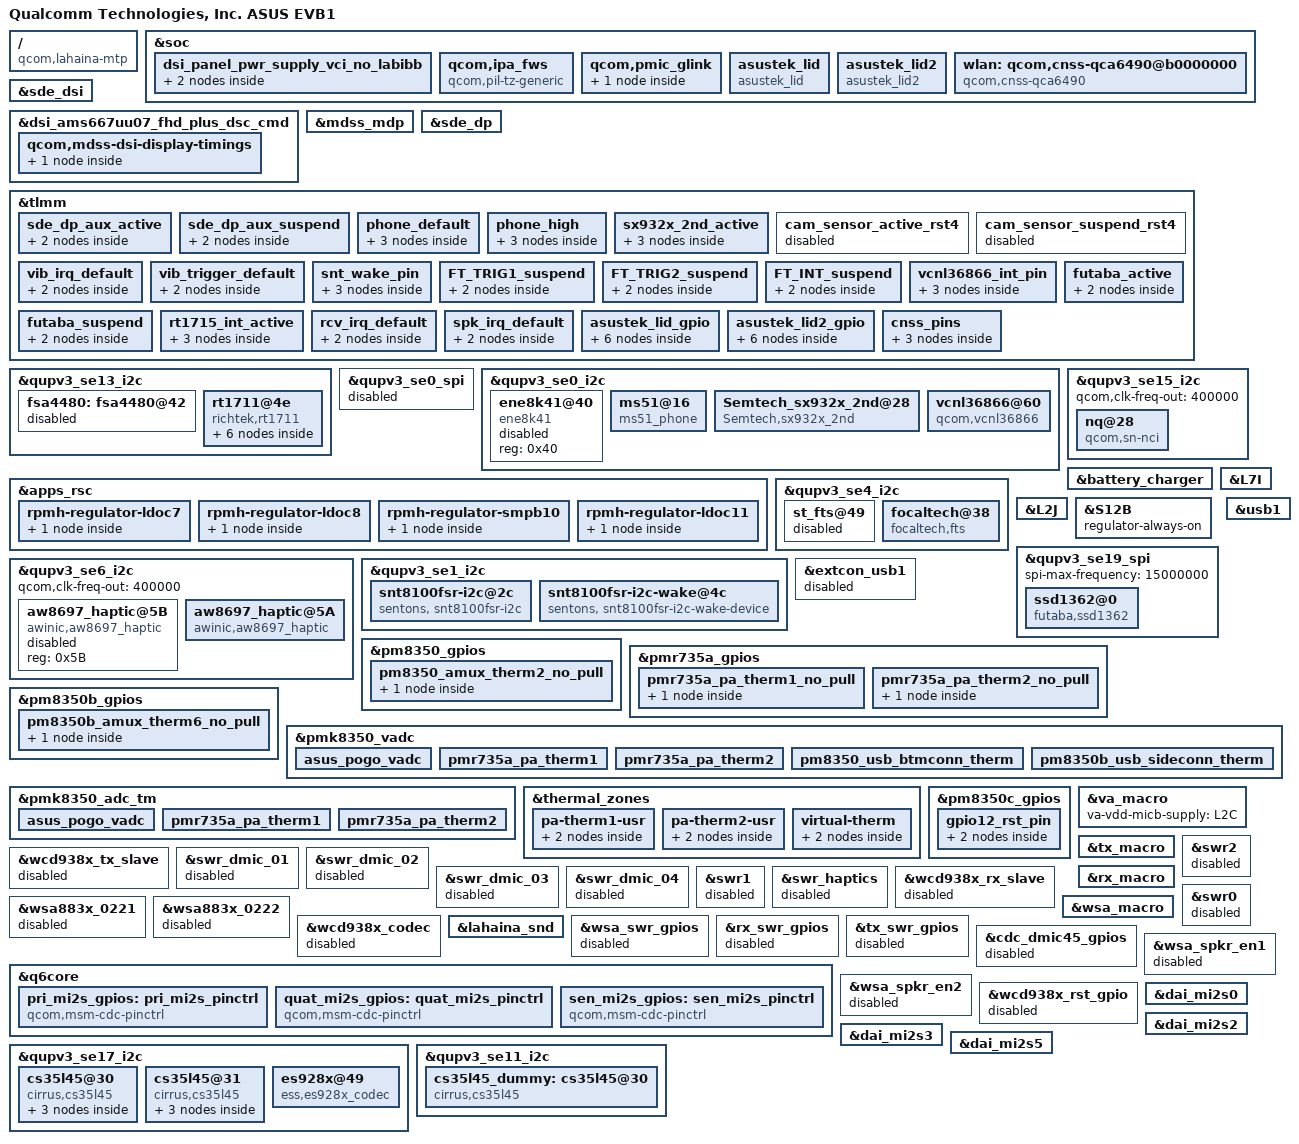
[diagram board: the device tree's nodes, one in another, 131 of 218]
/dts-v1/;
/plugin/;

#include "lahaina-mtp.dtsi"
/* ASUS BSP Display +++ */
#include "dsi-panel-ams667uu07-fhd-plus-dsc-cmd.dtsi"

/* ASUS BSP Camera +++ */
#include "camera/zs673ks-camera-sensor-mtp.dtsi"

/ {
	model = "Qualcomm Technologies, Inc. ASUS EVB1";
	compatible = "qcom,lahaina-mtp", "qcom,lahaina", "qcom,mtp";
	qcom,board-id = <0x10008 0>;
};

/*   ====================================
*    overlay for display - start
*    ====================================
*/
&soc {
	dsi_panel_pwr_supply_vci_no_labibb: dsi_panel_pwr_supply_vci_no_labibb {
		#address-cells = <1>;
		#size-cells = <0>;

		qcom,panel-supply-entry@0 {
			reg = <0>;
			qcom,supply-name = "vddio";
			qcom,supply-min-voltage = <1800000>;
			qcom,supply-max-voltage = <1800000>;
			qcom,supply-enable-load = <60700>;
			qcom,supply-disable-load = <80>;
		};

		qcom,panel-supply-entry@1 {
			reg = <1>;
			qcom,supply-name = "vdd";
			qcom,supply-min-voltage = <3000000>;
			qcom,supply-max-voltage = <3000000>;
			qcom,supply-enable-load = <10000>;
			qcom,supply-disable-load = <0>;
			qcom,supply-post-on-sleep = <0>;
			qcom,supply-pre-off-sleep = <10>;
		};
	};

};

&sde_dsi {
	/delete-property/ avdd-supply;
	qcom,dsi-default-panel = <&dsi_ams667uu07_fhd_plus_dsc_cmd>;

};

&dsi_ams667uu07_fhd_plus_dsc_cmd {
	qcom,panel-supply-entries = <&dsi_panel_pwr_supply_vci_no_labibb>;
	qcom,mdss-dsi-bl-pmic-control-type = "bl_ctrl_dcs";
	qcom,mdss-dsi-bl-min-level = <1>;
	qcom,mdss-dsi-bl-max-level = <4095>;

	qcom,platform-te-gpio = <&tlmm 82 0>; // default is 82
	qcom,platform-reset-gpio = <&tlmm 24 0>;
	qcom,platform-en-gpio = <&tlmm 74 0>;

	qcom,ulps-enabled;
	qcom,dsi-select-clocks = "mux_byte_clk0", "mux_pixel_clk0";
	qcom,mdss-dsi-display-timings {
		timing@0 {
			qcom,mdss-dsi-panel-phy-timings = [00 14 05 05 13 1E 05
				05 06 02 04 00 12 0A];
			qcom,display-topology = <2 2 1>;
			qcom,default-topology-index = <0>;
		};
	};
};

&mdss_mdp {
	qcom,sde-mixer-display-pref = "primary", "none", "none",
				"none", "none", "none";
};

&sde_dp {
	/delete-property/ qcom,dp-aux-switch;
	qcom,dp-gpio-aux-switch;

	qcom,aux-en-gpio = <&tlmm 93 0>;
	qcom,aux-sel-gpio = <&pm8350c_gpios 1 0x0>;


	pinctrl-names = "mdss_dp_active", "mdss_dp_sleep";
	pinctrl-0 = <&sde_dp_aux_active >;
	pinctrl-1 = <&sde_dp_aux_suspend>;
};

&tlmm {
	/delete-property/ display_panel_avdd_default;

	sde_dp_aux_active: sde_dp_aux_active {
		mux {
			pins = "gpio93";
			function = "gpio";
		};

		config {
			pins = "gpio93";
			bias-disable = <0>; /* no pull */
			drive-strength = <8>;
		};
	};

	sde_dp_aux_suspend: sde_dp_aux_suspend {
		mux {
			pins = "gpio93";
			function = "gpio";
		};

		config {
			pins = "gpio93";
			bias-disable = <0>; /* no pull */
			drive-strength = <2>;
		};
	};
	//ASUS_BSP+++ "AntennaSwap"
	phone_default {
	    phone_default_1: phone_default_1{
		    mux {
			    pins = "gpio83";
			    function = "gpio";
		    };
		    config {
			    pins = "gpio83";
			    bias-pull-up;
			    output-low;
		    };
	    };
	};

	phone_high {
	    phone_high_1: phone_high_1{
		    mux {
			    pins = "gpio83";
			    function = "gpio";
		    };
		    config {
			    pins = "gpio83";
			    bias-pull-up;
			    output-high;
		    };
	    };
	};
	//ASUS_BSP--- "AntennaSwap"
};

&qupv3_se13_i2c {
	fsa4480: fsa4480@42 {
		status = "disable";
	};
};
/*   ====================================
*    overlay for display - end
*    ====================================
*/

/*    ====================================
 *    overlay for lahainap-v2.dtsi - start
 *    ====================================
 */

/*    ====================================
 *    overlay for lahainap-v2.dtsi - end
 *    ====================================
 */



/*    ====================================
 *    overlay for lahainap.dtsi - start
 *    ====================================
 */

/*    ====================================
 *    overlay for lahainap.dtsi - end
 *    ====================================
*/



/*    ====================================
 *    overlay for lahaina-mtp.dtsi - start
 *    ====================================
 */

&qupv3_se0_spi {
	status = "disable";
};

&qupv3_se0_i2c {
	status = "ok";

	ene8k41@40 {
		compatible = "ene8k41";
		reg = <0x40>;
		//ene,aura_3p3_en = <&tlmm 108 0x0>;
		//pinctrl-names = "active";
		//pinctrl-0 = <&aura_3p3_en>;
		status = "disabled";
	};

	ms51@16 {
		compatible = "ms51_phone";
		reg = <0x16>;

		//panel = <&dsi_r66451_fhd_video &dsi_r66451_fhd_dsc_cmd_dim>;
		nuvoton,aura_3p3_en = <0 0 0>;
		nuvoton,front_led_en = <&pm8350c_gpios 2 0x0>;
		nuvoton,logo_5p0_en = <&pm8350c_gpios 3 0x0>;
		nuvoton,hw_stage = <0>;

		vdd-supply = <&pm8350c_l7>;
		nuvoton,vdd-voltage = <3300000 3300000>;
		nuvoton,vdd-current = <140000>;
	};
};

&apps_rsc {
	rpmh-regulator-ldoc7 {
		L7C: pm8350c_l7: regulator-pm8350c-l7 {
			regulator-min-microvolt = <3300000>;
			regulator-max-microvolt = <3300000>;
			qcom,init-voltage = <3300000>;
		};
	};
};

//ASUS_BSP BerylHou +++ 
//"touch FT3518U" +++
 &qupv3_se4_i2c {
  	status = "ok";

  	st_fts@49 {
		status = "disable";
	};
  	
	focaltech@38 {
		compatible = "focaltech,fts";
		reg = <0x38>;
		interrupt-parent = <&tlmm>;
		interrupts = <23 0x2008>;
		focaltech,reset-gpio = <&tlmm 22 0x00>;
		focaltech,irq-gpio = <&tlmm 23 0x2008>;
		focaltech,vddio = <&tlmm 131 0x00>;
		focaltech,max-touch-number = <10>;
		focaltech,display-coords = <0 0 1080 2400>;

		vdd-supply = <&L3C>;
		vcc_i2c-supply = <&L8C>;

		pinctrl-names = "pmx_ts_active", "pmx_ts_suspend","pmx_ts_release";
		pinctrl-0 = <&ts_active>;
		pinctrl-1 = <&ts_int_suspend &ts_reset_suspend>;
		pinctrl-2 = <&ts_release>;

//		panel = <&dsi_ams667uu07_fhd_plus_dsc_cmd>;
//			 &dsi_r66451_amoled_video>;
	};
};

&qupv3_se15_i2c{
	status = "ok";
	qcom,clk-freq-out = <400000>;

	nq@28 {
		compatible = "qcom,sn-nci";
		reg = <0x29>;
		qcom,sn-irq = <&tlmm 87 0x00>;
		qcom,sn-ven = <&tlmm 62 0x00>;
		qcom,sn-firm = <&tlmm 86 0x00>;
		qcom,sn-clkreq = <&tlmm 63 0x00>;
		interrupt-parent = <&tlmm>;
		interrupts = <87 0>;
		interrupt-names = "nfc_irq";
		pinctrl-names = "nfc_active", "nfc_suspend";
		pinctrl-0 = <&nfc_int_active &nfc_enable_active
				&nfc_clk_req_active &nfc_fwdl_active>;
		pinctrl-1 = <&nfc_int_suspend &nfc_enable_suspend
				&nfc_clk_req_suspend &nfc_fwdl_suspend>;
	};
};

//"touch FT3518U" ---
//cap sensor 1  SX9325" +++
/* &qupv3_se15_i2c{
	status = "ok";
	Semtech_sx932x@28 {
	compatible = "Semtech,sx932x";
	reg = <0x28>;
	//interrupt-parent = <&tlmm>;
	//interrupts = <99 0>;
	pinctrl-names = "sx932x_1st_active";
	pinctrl-0 = <&sx932x_1st_active>;
		
	Semtech,nirq-gpio = <&tlmm 99 0x00>;
	status = "ok";
	Semtech,reg-num = <45>; // total registers number to initialize
	Semtech,reg-init  = /bits/ 8 < 0x10 0x1C
                                0x11 0x21
                                0x14 0x00
                                0x15 0x00
                                0x20 0x20
                                0x23 0x00
                                0x24 0x47
                                0x26 0x00
                                0x27 0x47
                                0x28 0x39
                                0x29 0x2D
                                0x2A 0x36
                                0x2B 0x07
                                0x2C 0x12
                                0x2D 0x08
                                0x30 0x21
                                0x31 0x0B
                                0x32 0x20
                                0x33 0x20
                                0x34 0x0C
                                0x35 0x00
                                0x36 0x8E
                                0x37 0xB3
                                0x40 0x00
                                0x41 0x00
                                0x42 0x00
                                0x43 0x00
                                0x44 0x00
                                0x45 0x05
                                0x46 0x00
                                0x47 0x00
                                0x48 0x00
                                0x49 0x00
                                0x4A 0x00
                                0x4B 0x00
                                0x4C 0x00
                                0x50 0x14
                                0x51 0x70
                                0x52 0x20
                                0x02 0x00
                                0x05 0x6F
                                0x06 0x00
                                0x07 0x80
                                0x08 0x01
                                0x03 0x0F>;
	};
 };
 
 &tlmm{
	sx932x_active {
		sx932x_1st_active: sx932x_1st_active {
			mux {
				pins = "gpio99";
				function = "gpio";
			};
			config {
				pins = "gpio99";
				bias-pull-up;
				drive-strength = <6>;
			};
		};
	};
  };
*/
//"cap sensor 1  SX9325" ---
//"cap sensor 2  SX9325" +++
 &qupv3_se0_i2c{
	status = "ok";
	Semtech_sx932x_2nd@28 {
	compatible = "Semtech,sx932x_2nd";
	reg = <0x28>;
	pinctrl-names = "sx932x_2nd_active";
	pinctrl-0 = <&sx932x_2nd_active>;
		
	Semtech,nirq-gpio = <&tlmm 91 0x00>;
	status = "ok";	/**/
	Semtech,reg-num = <45>; /* total registers number to initialize*/
	Semtech,reg-init  = /bits/ 8 < 0x10 0x1C
                                0x11 0x21
                                0x14 0x00
                                0x15 0x00
                                0x20 0x20
                                0x23 0x00
                                0x24 0x47
                                0x26 0x00
                                0x27 0x47
                                0x28 0x39
                                0x29 0x2D
                                0x2A 0x36
                                0x2B 0x07
                                0x2C 0x12
                                0x2D 0x08
                                0x30 0x21
                                0x31 0x0B
                                0x32 0x20
                                0x33 0x20
                                0x34 0x0C
                                0x35 0x00
                                0x36 0x8E
                                0x37 0xB3
                                0x40 0x00
                                0x41 0x00
                                0x42 0x00
                                0x43 0x00
                                0x44 0x00
                                0x45 0x05
                                0x46 0x00
                                0x47 0x00
                                0x48 0x00
                                0x49 0x00
                                0x4A 0x00
                                0x4B 0x00
                                0x4C 0x00
                                0x50 0x14
                                0x51 0x70
                                0x52 0x20
                                0x02 0x00
                                0x05 0x6F
                                0x06 0x00
                                0x07 0x80
                                0x08 0x01
                                0x03 0x0F>;
	};
};

&tlmm{
	sx932x_2nd_active {
		sx932x_2nd_active: sx932x_2nd_active {
			mux {
				pins = "gpio91";
				function = "gpio";
			};
			config {
				pins = "gpio91";
				bias-pull-up;
				drive-strength = <6>;
			};
		};
	};
};
//"cap sensor 2  SX9325" ---
//ASUS_BSP BerylHou --- 

//ASUS_BSP: haptic vibrator+++

&tlmm {
		cam_sensor_active_rst4: cam_sensor_active_rst4 {
			status = "disable";
		};
		cam_sensor_suspend_rst4: cam_sensor_suspend_rst4 {
			status = "disable";
		};

		vib_irq_default: vib_irq_default{
			mux {
				pins = "gpio98";
				function = "gpio";
			};

			config {
				pins = "gpio98";
				drive-strength = <2>;
				bias-pull-up;
				input-enable;
				};
		};

		vib_trigger_default: vib_trigger_default{
			mux {
				pins = "gpio97";
				function = "gpio";
			};

			config {
				pins = "gpio97";
				drive-strength = <2>;
				bias-disable;
				output-low;
			};
		};
};

//ASUS_BSP: aw haptic +++
&qupv3_se6_i2c {
	status = "ok";
	#address-cells = <1>;
	#size-cells = <0>;

	//+++for 400kHz i2c clock
	qcom,clk-freq-out = <400000>;
	//---

	aw8697_haptic@5B {
		compatible = "awinic,aw8697_haptic";
		reg = <0x5B>;
		status = "disabled";
	};

	aw8697_haptic@5A {
		compatible = "awinic,aw8697_haptic";
		reg = <0x5A>;
		interrupt-parent = <&tlmm>;
		interrupts = <98 0>; // set type in driver IRQ_TYPE_NONE
		irq-gpio = <&tlmm 98 0>; // set type in driver IRQ_TYPE_NONE
		vib_mode = < 0 >;   /*mode:   RAM mode->0; CONT mode -> 1*/
		vib_f0_pre = < 1500 >; // 150Hz
		vib_f0_cali_percen = < 7 >;
		vib_cont_drv_lev = < 100 >; // 2*1.414*255/6.1
		vib_cont_drv_lvl_ov = < 100 >;
		vib_cont_td = < 0x006c >;
		vib_cont_zc_thr = < 0x0ff1 >;
		vib_cont_num_brk = < 3 >;
		vib_f0_coeff = < 260 >; /*Don't modify it    2.604167*/
		vib_f0_trace_parameter = < 0x05 0x03 0x02 0x0f >;
		vib_bemf_config = < 0x10 0x08 0x03 0xf8 >;
		vib_sw_brake = < 0x2c >;
		vib_tset = < 0x12 >;
		vib_r_spare = < 0x68 >;
		vib_bstdbg = < 0x30 0xeb 0xd4 0 0 0 >;
		pinctrl-names = "default";
		pinctrl-states = "default";
		pinctrl-0 = <&vib_irq_default>;
		status = "okay";
	};
};
//ASUS_BSP: aw haptic ---
//ASUS_BSP: haptic vibrator---

//[+++] ASUS_BSP : Add for battery_charger
&battery_charger {
	PMI_MUX_EN = <&pm8350_gpios 2 0x0>;
	POGO_OTG_EN = <&tlmm 3 0x0>;
};
//[---] ASUS_BSP : Add for battery_charger

// ASUS_BSP +++ ClayWang vcnl36866
&qupv3_se0_i2c {
        status = "ok";
            vcnl36866@60 {
			compatible = "qcom,vcnl36866";
			reg = <0x60>;
			pinctrl-names = "alsps_gpio_no_pull";
			pinctrl-0 = <&vcnl36866_default>;
			qcom,alsps-gpio = <&tlmm 89 0x0>;
			vcc_psensor-supply = <&pm8350c_l7>;
			
		};
};

&apps_rsc {
	// ASUS BSP +++ Clay vcnl36866
	rpmh-regulator-ldoc8 {
		L8C: pm8350c_l8: regulator-pm8350c-l8 {
			regulator-always-on;	/* ASUS BSP Always Enable 1.8V for I2C & Sensors */
		};
	};

	// ASUS BSP --- Clay vcnl36866
	// ASUS BSP +++ Clay Grip
	rpmh-regulator-smpb10 {
		S10B: pm8350_s10: regulator-pm8350-s10 {
			regulator-min-microvolt = <1800000>;
			regulator-max-microvolt = <1800000>;
			qcom,init-voltage = <1800000>;
		};
	};
	// ASUS BSP --- Clay Grip
	
};

//ASUS_BSP RIL+++
&soc {
	qcom,ipa_fws {
		compatible = "qcom,pil-tz-generic";
		vdd-3.0-antenna-supply = <&pm8350c_l11>;
		pinctrl-names = "phone_default", "phone_high";
		pinctrl-0 = <&phone_default_1>;
		pinctrl-1 = <&phone_high_1>;
		phone-asus_ant_83 = <&tlmm 83 0>;
	};
};

&apps_rsc {
	rpmh-regulator-ldoc11 {
		L11C: pm8350c_l11: regulator-pm8350c-l11 {
			regulator-min-microvolt = <2850000>;
			regulator-max-microvolt = <2850000>;
			qcom,init-voltage = <2850000>;
		};
	};
};
//ASUS_BSP RIL---
 
// ASUS_BSP Grip +++
&qupv3_se1_i2c {
	status = "ok";
	snt8100fsr-i2c@2c {
		reg = <0x2c>;
		compatible = "sentons, snt8100fsr-i2c";
		
		qcom,snt-host1-gpio = <&tlmm 165 0x0>;
		qcom,snt-trig0-gpio = <&tlmm 155 0x0>;
		qcom,snt-trig1-gpio = <&tlmm 154 0x0>;
		//qcom,snt-trig2-gpio = <&tlmm 66 0x0>;
		//qcom,snt-trig3-gpio = <&tlmm 167 0x0>;
		snt-id-gpio = <&tlmm 132 GPIO_ACTIVE_HIGH>;
		//snt,gpio_reset = <&tlmm 4 0x0>;
		vcc_grip_2v8-supply = <&pm8008i_l7>;
		vcc_grip_1v2-supply = <&pm8008j_l2>;
		vcc_grip_1v2Base-supply = <&pm8350_s12>;
		vcc_grip_1v8-supply = <&pm8350_s10>;
		
		pinctrl-names = "gpio12_rst_on", "gpio12_rst_off", "snt_wake", "FT_TRIG1_suspend", "FT_TRIG2_suspend", "FT_INT_suspend";
		pinctrl-0 = <&gpio12_rst_pin_default>;
		pinctrl-1 = <&gpio12_rst_off>;
		pinctrl-2 = <&snt_wake>;
		pinctrl-3 = <&FT_TRIG1_suspend>;
		pinctrl-4 = <&FT_TRIG2_suspend>;
		pinctrl-5 = <&FT_INT_suspend>;
		rst_gpios = <&pm8350c_gpios 4 GPIO_ACTIVE_HIGH>;
		//rst_gpios = <&tlmm 167 GPIO_ACTIVE_HIGH>;
	};
	snt8100fsr-i2c-wake@4c {
		reg = <0x4c>;
		wake-device = <1>;
		compatible = "sentons, snt8100fsr-i2c-wake-device";
	};
};

&tlmm {
	snt_wake_pin {
		snt_wake: snt_wake {
			mux {
				pins = "gpio85";
				function = "gpio";
			};
			config {
				pins = "gpio85";
				bias-disable = <0>; /* no pull */
				drive-strength = <2>;
			};
		};
	};
	FT_TRIG1_suspend: FT_TRIG1_suspend {
		mux {
			pins = "gpio155";
			function = "gpio";
		};

		config {
			pins = "gpio155";
			bias-disable = <0>; /* no pull */
			drive-strength = <2>;
		};
	};

	FT_TRIG2_suspend: FT_TRIG2_suspend {
		mux {
			pins = "gpio154";
			function = "gpio";
		};

		config {
			pins = "gpio154";
			bias-disable = <0>; /* no pull */
			drive-strength = <2>;
		};
	};

	FT_INT_suspend: FT_INT_suspend {
		mux {
			pins = "gpio165";
			function = "gpio";
		};

		config {
			pins = "gpio165";
			bias-disable = <0>; /* no pull */
			drive-strength = <2>;
		};
	};
	// ASUS_BSP +++ ClayWang vcnl36866
	vcnl36866_int_pin {
		vcnl36866_default: vcnl36866_default {
			mux {
				pins = "gpio89";
				function = "gpio";
			};
			config {
				pins = "gpio89";
				bias-disable = <0>; /* no pull */
				drive-strength = <2>;
			};
		};
	};
	// ASUS_BSP --- ClayWang vcnl36866
};

&L7I {
	regulator-min-microvolt = <2800000>;
	regulator-max-microvolt = <2800000>;
	qcom,min-dropout-voltage = <300000>;
};
&L2J {
	regulator-max-microvolt = <1256000>;
	qcom,min-dropout-voltage = <0>;
};
&S12B {
	regulator-always-on;
};
// ASUS_BSP Grip ---

//ASUS_BSP PMOLED +++
&qupv3_se19_spi {
	status = "ok";
	spi-max-frequency = <15000000>;

	ssd1362@0 {
		compatible = "futaba,ssd1362";
		reg = <0>;
		spi-max-frequency = <15000000>;
		futaba,id-gpio = <&tlmm 75 0>;
		futaba,reset-gpio = <&tlmm 120 0>;
		futaba,dc-gpio = <&tlmm 121 0>;
		futaba,pwren-gpio = <&tlmm 122 0>;

		pinctrl-names = "futaba_active", "futaba_suspend";
		pinctrl-0 = <&futaba_active>;
		pinctrl-1 = <&futaba_suspend>;
	};
};

&tlmm {
/* futaba pmoled pins */
	futaba_active: futaba_active {
		mux {
			pins = "gpio75", "gpio120", "gpio121", "gpio122";
			function = "gpio";
		};
	config {
		pins = "gpio75", "gpio120", "gpio121", "gpio122";
		drive-strength = <8>;
		bias-pull-up;
		};
	};

	futaba_suspend: futaba_suspend {
		mux {
			pins = "gpio75", "gpio120", "gpio121", "gpio122";
			function = "gpio";
		};

	config {
		pins = "gpio75", "gpio120", "gpio121", "gpio122";
		drive-strength = <2>;
		bias-pull-down;
		};
	};
};
//ASUS_BSP PMOLED ---

//ASUS BSP Richtek TypeC PD +++
&qupv3_se13_i2c {
	status = "ok";
	rt1711@4e {
		compatible = "richtek,rt1711";
		reg = <0x4e>;
		rt1711,irq_pin = <&tlmm 118 0x00>;
		rt-dual,supported_modes = <0>; /* 0: dfp/ufp, 1: dfp, 2: ufp */
		rt-tcpc,name = "type_c_port0"; /* tcpc_device's name */
		rt-tcpc,role_def = <4>; /* 0: SNK Only, 1: SRC Only, 2: DRP, 3: Try.SRC, 4: Try.SNK */
		rt-tcpc,rp_level = <0>; /* 0: Default, 1: 1.5, 2: 3.0 */
		rt-tcpc,vconn_supply  = <1>;  /* 0: Never, 1: Always, 2: EMarkOnly, 3: StartOnly */
		rt-tcpc,notifier_supply_num = <1>; /* the number of notifier supply */
		pinctrl-names = "rt1715_int_active";
		pinctrl-0 = <&rt1715_int_active>;
		BTM_OTG_EN = <&pm8350c_gpios 4 0x0>;
		BTM_OTG_EN_ER = <&tlmm 66 0x0>;
		pd-data {
			pd,vid = <0x29cf>;
			pd,pid = <0x5081>;
			pd,source-cap-ext = <0x171129cf 0x00000000 0x00000102 0x00000000 0x00000000 0x02000000>;
			pd,mfrs = "RichtekTCPC";

			/*
			 *	VSAFE5V = 0, MAX_POWER = 1, CUSTOM = 2,
			 *	MAX_POWER_LV = 0x21, MAX_POWER_LVIC = 0x31
			 *	MAX_POWER_HV = 0x41, MAX_POWER_HVIC = 0x51
			 */
				pd,charging_policy= <0x21>;

			/*
			 * Fixed 5V, 500 mA <0x00019032>
			 * Fixed 5V, 1A <0x00019064>
			 * Fixed 5V, 2A <0x000190c8>
			 * Fixed 5V, 3A <0x0001912c>
			 * Fixed 9V, 500 mA <0x0002d032>
			 * Fixed 9V, 1A <0x0002d064>
			 * Fixed 9V, 2A <0x0002d0c8>
			 * Fixed 9V, 3A <0x0002d12c>
			 * Variable 5-9V, 1A <0x8642d064>
			 * Variable 5-9V, 2A <0x8642d0c8>
			 * Variable 5-9V, 3A <0x8642d12c>
			 * PPS 3V~5.9V, 3A <0xC0761E3C>
			 */
				pd,source-pdo-size = <1>;
				pd,source-pdo-data = <0x00019032>; /* 5V, 500 mA */
				pd,sink-pdo-size = <2>;
				pd,sink-pdo-data = <0x000190c8 0x000190c8> ;   /* 0x0002d0c8 : 9V, 2A<0x04019032 0x04019064> */

			/*
			 * No DP, host + device
			 *	pd,id-vdo-size = <3>;
					pd,id-vdo-data = <0xd00029cf 0x0 0x00010000>;
			 * With DP
			 *	pd,id-vdo-size = <4>;
					pd,id-vdo-data = <0xec0029cf 0x0 0x00010000 0x11000001>;
			 */

				pd,id-vdo-size = <3>;
				pd,id-vdo-data = <0xd00029cf 0x0 0x00010000>;

			bat,nr = <1>;
			pd,country_nr = <0>;

			bat-info0 {
				bat,vid = <0x29cf>;
				bat,pid = <0x1711>;
				bat,mfrs = "bat1";
				bat,design_cap = <3000>;
			};

			//bat-info1 {
			//	bat,vid = <0x8abc>;
			//	bat,pid = <0x5234>;
			//	bat,mfrs = "bat2";
			//	bat,design_cap = <4000>;
			//};

			//country0 {
			//	pd,country_code = <0x5457>;
			//	pd,country_len = <2>; /* max len = 26 */
			//	pd,country_data = <0xff 0xff>;
			//};

			//country1 {
			//	pd,country_code = <0x5553>;
			//	pd,country_len = <3>; /* max len = 26 */
			//	pd,country_data = <0xf1 0xf2 0xf3>;
			//};
		};

		dpm_caps {
			local_dr_power;
			local_dr_data;
			//local_ext_power;
			local_usb_comm;
			//local_usb_suspend;
			//local_high_cap;
			//local_give_back;
			local_no_suspend;
			local_vconn_supply;

			//attemp_discover_cable_dfp;
			attemp_enter_dp_mode;
			//attemp_discover_cable;
			attemp_discover_id;
			/* 0: disable, 1: prefer_snk, 2: prefer_src */
			pr_check = <0>;
			//pr_reject_as_source;
			//pr_reject_as_sink;
			pr_check_gp_source;
			//pr_check_gp_sink;

			/* 0: disable, 1: prefer_ufp, 2: prefer_dfp */
			dr_check = <0>;
			//dr_reject_as_dfp;
			//dr_reject_as_ufp;
		};
		displayport {
			/* connection type = "both", "ufp_d", "dfp_d" */
			1st_connection = "dfp_d";
			2nd_connection = "dfp_d";
			signal,dp_v13;
			//signal,dp_gen2;
			usbr20_not_used;
			typec,receptacle;
			ufp_d {
				//pin_assignment,mode_a;
				//pin_assignment,mode_b;
				//pin_assignment,mode_c;
				//pin_assignment,mode_d;
				//pin_assignment,mode_e;
			};
			dfp_d {
				/* Only support mode C & D */
				//pin_assignment,mode_a;
				//pin_assignment,mode_b;
				pin_assignment,mode_c;
				pin_assignment,mode_d;
				pin_assignment,mode_e;
				pin_assignment,mode_f;
			};
		};
	};
};

&extcon_usb1 {
	status = "disable";
};

&soc {
	qcom,pmic_glink {
		richtek,rt-charger {
			compatible = "richtek,rt-charger";
			//vconn-supply = <&vconn_5v>;
		};
	};
};
//ASUS BSP Richtek TypeC PD ---
&usb1 {
	extcon = <0>;
	adsp-usb2-switch;
	qcom,usb-charger = <&battery_charger>;
};

&tlmm {
	//ASUS BSP Richtek TypeC PD +++
	rt1715_int_active {
		rt1715_int_active: rt1715_int_active {
			mux {
				pins = "gpio118";
				function = "gpio";
			};

			config {
				pins = "gpio118";
				drive-strength = <2>;
				bias-pull-up;
			};
		};
	};
	//ASUS BSP Richtek TypeC PD ---
};

/*    ====================================
 *    overlay for lahaina-mtp.dtsi - end
 *    ====================================
 */


/*    ====================================
 *    overlay for lahaina-pm.dtsi - start
 *    ====================================
 */

/*    ====================================
 *    overlay for lahaina-pm.dtsi - end
 *    ====================================
 */



/*    ====================================
 *    overlay for lahaina-pinctrl.dtsi - start
 *    ====================================
 */

/*    ====================================
 *    overlay for lahaina-pinctrl.dtsi - end
 *    ====================================
 */



/*    ====================================
 *    overlay for lahaina-pmic-overlay.dtsi - start
 *    ====================================
 */
 
//[+++] ASUS_BSP : Don't use GPIO1 of PMIC8350 for cam
//#if 0
&pm8350_gpios {

	/delete-node/ pm8350_rear_tof_therm;	

};

&pmr735a_gpios {
	pmr735a_pa_therm1_no_pull {
		pmr735a_pa_therm1_no_pull_default: pmr735a_pa_therm1_no_pull_default {
			pins = "gpio1";
			bias-disable;
		};
	};

	pmr735a_pa_therm2_no_pull {
		pmr735a_pa_therm2_no_pull_default: pmr735a_pa_therm2_no_pull_default {
			pins = "gpio2";
			bias-disable;
		};
	};
};

&pm8350b_gpios {
	pm8350b_amux_therm6_no_pull {
		pm8350b_amux_therm6_no_pull_default: pm8350b_amux_therm6_no_pull_default {
			pins = "gpio6";
			input-enable;
			bias-disable;
		};
	};
};

&pm8350_gpios {
	pm8350_amux_therm2_no_pull {
		pm8350_amux_therm2_no_pull_default: pm8350_amux_therm2_no_pull_default {
			pins = "gpio2";
			bias-disable;
		};
	};
};

&pmk8350_vadc {

	pinctrl-names = "default";
	pinctrl-0 = <&pmr735a_pa_therm1_no_pull_default &pmr735a_pa_therm2_no_pull_default &pm8350b_amux_therm6_no_pull_default &pm8350_amux_therm2_no_pull_default>;

	/delete-node/ pm8350_rear_tof_therm;
	/delete-node/ pm8350b_wl_chg_therm;
	/delete-node/ pm8350_cam_flash_therm;
	/delete-node/ pm8350_wide_rfc_therm;

	asus_pogo_vadc {
		reg = <PM8350_ADC7_AMUX_THM4>;
		label = "asus_pogo_vadc";
		qcom,hw-settle-time = <200>;
		qcom,pre-scaling = <1 1>;
	};
		
	pmr735a_pa_therm1 {
		reg = <PMR735A_ADC7_GPIO1_100K_PU>;
		label = "pmr735a_pa_therm1";
		qcom,ratiometric;

		qcom,hw-settle-time = <200>;
		qcom,pre-scaling = <1 1>;
	};	
	pmr735a_pa_therm2 {
		reg = <PMR735A_ADC7_GPIO2_100K_PU>;
		label = "pmr735a_pa_therm2";
	
		qcom,ratiometric;
		qcom,hw-settle-time = <200>;
		qcom,pre-scaling = <1 1>;
	};	
	pm8350_usb_btmconn_therm {
		reg = <PM8350_ADC7_AMUX_THM2_100K_PU>;
		label = "pm8350_usb_btmconn_therm";
		qcom,ratiometric;
		qcom,hw-settle-time = <200>;
		qcom,pre-scaling = <1 1>;
	};
	pm8350b_usb_sideconn_therm {
		reg = <PM8350B_ADC7_AMUX_THM6_100K_PU>;
		label = "pm8350b_usb_sideconn_therm";
		qcom,ratiometric;
		qcom,hw-settle-time = <200>;
		qcom,pre-scaling = <1 1>;
	};	
};
&pmk8350_adc_tm {

	io-channels = <&pmk8350_vadc PM8350_ADC7_AMUX_THM4>,
			<&pmk8350_vadc PM8350_ADC7_AMUX_THM1_100K_PU>,
			<&pmk8350_vadc PM8350_ADC7_AMUX_THM3_100K_PU>,
			<&pmk8350_vadc PM8350B_ADC7_AMUX_THM4_100K_PU>,
			<&pmk8350_vadc PMK8350_ADC7_AMUX_THM1_100K_PU>,
			<&pmk8350_vadc PMR735A_ADC7_GPIO1_100K_PU>,
			<&pmk8350_vadc PMR735A_ADC7_GPIO2_100K_PU>;

	/delete-node/ pm8350_rear_tof_therm;
	/delete-node/ pm8350b_wl_chg_therm;
	/delete-node/ pm8350_cam_flash_therm;
	/delete-node/ pm8350_wide_rfc_therm;

	asus_pogo_vadc {
		reg = <PM8350_ADC7_AMUX_THM4>;
		qcom,kernel-client;
		qcom,scale-type = <0>;
		qcom,prescaling = <1>;
	};

	pmr735a_pa_therm1 {
		reg = <PMR735A_ADC7_GPIO1_100K_PU>;
		qcom,ratiometric;
		qcom,hw-settle-time = <200>;
	};
		
	pmr735a_pa_therm2 {
		reg = <PMR735A_ADC7_GPIO2_100K_PU>;
		qcom,ratiometric;
		qcom,hw-settle-time = <200>;
	};
};

&thermal_zones {
	/delete-node/ rear-cam-therm-usr;
	/delete-node/ tof-therm-usr;
	/delete-node/ wlc-therm-usr;
	/delete-node/ camera-therm-usr;
	
	pa-therm1-usr {
		polling-delay-passive = <0>;
		polling-delay = <0>;
		thermal-governor = "user_space";
		thermal-sensors = <&pmk8350_adc_tm PMR735A_ADC7_GPIO1_100K_PU>;
		wake-capable-sensor;
		trips {
			active-config0 {
				temperature = <125000>;
				hysteresis = <1000>;
				type = "passive";
			};
		};
	};
	
	pa-therm2-usr {
		polling-delay-passive = <0>;
		polling-delay = <0>;
		thermal-governor = "user_space";
		thermal-sensors = <&pmk8350_adc_tm PMR735A_ADC7_GPIO2_100K_PU>;
		wake-capable-sensor;
		trips {
			active-config0 {
				temperature = <125000>;
				hysteresis = <1000>;
				type = "passive";
			};
		};
	};
	
	virtual-therm {
		polling-delay-passive = <0>;
		polling-delay = <0>;
		thermal-governor = "user_space";
		thermal-sensors = <&pmk8350_adc_tm PM8350_ADC7_AMUX_THM1_100K_PU>;
		wake-capable-sensor;
		trips {
			active-config0 {
				temperature = <125000>;
				hysteresis = <1000>;
				type = "passive";
			};
		};
	};
};

//[--] ASUS_BSP : Don't use GPIO1 of PMIC8350 for cam

/*    ====================================
 *    overlay for lahaina-pmic-overlay.dtsi - end
 *    ====================================
 */


/*    ====================================
 *    overlay for pm8350.dtsi - start
 *    ====================================
 */

/*    ====================================
 *    overlay for pm8350.dtsi - end
 *    ====================================
 */


/*    ====================================
 *    overlay for pmk8350.dtsi - start
 *    ====================================
 */

/*    ====================================
 *    overlay for pmk8350.dtsi - end
 *    ====================================
 */

/*    ====================================
 *    overlay for pm8350b.dtsi - start
 *    ====================================
 */

/*    ====================================
 *    overlay for pm8350b.dtsi - end
 *    ====================================
 */

/*    ====================================
 *    overlay for pm8350c.dtsi - start
 *    ====================================
 */

&pm8350c_gpios {
	gpio12_rst_pin {
		gpio12_rst_pin_default: gpio12_rst_pin_default {
			pins = "gpio4"; 
			function = "normal"; 
			power-source = <0>; 
			output-low; 
			input-disable;
		};
		
		gpio12_rst_off: gpio12_rst_off {
			pins = "gpio4"; 
			function = "normal"; 
			bias-disable;
			output-low; 
			power-source = <0>; 
		};
	};
};

/*    ====================================
 *    overlay for pm8350c.dtsi - end
 *    ====================================
 */


/*    ====================================
 *    overlay for lahaina-regulators.dtsi - start
 *    ====================================
 */

/*    ====================================
 *    overlay for lahaina-regulators.dtsi - end
 *    ====================================
 */
  

 
/*    ====================================
 *    overlay for lahaina-audio.dtsi - start
 *    ====================================
 */

&va_macro {
	va-vdd-micb-supply = <&L2C>;
};

&tx_macro {
	qcom,is-used-swr-gpio = <0>;
	qcom,tx-swr-gpios;
};

&swr2 {
	status = "disabled";
};

&wcd938x_tx_slave {
	status = "disabled";
};

&swr_dmic_01 {
	status = "disabled";
};

&swr_dmic_02 {
	status = "disabled";
};

&swr_dmic_03 {
	status = "disabled";
};

&swr_dmic_04 {
	status = "disabled";
};

&rx_macro {
	qcom,is-used-swr-gpio = <0>;
	qcom,rx-swr-gpios;
};

&swr1 {
	status = "disabled";
};

&swr_haptics {
	status = "disabled";
};

&wcd938x_rx_slave {
	status = "disabled";
};

&wsa_macro {
	qcom,is-used-swr-gpio = <0>;
	qcom,wsa-swr-gpios;
};

&swr0 {
	status = "disabled";
};

&wsa883x_0221 {
	status = "disabled";
};

&wsa883x_0222 {
	status = "disabled";
};

&wcd938x_codec {
	status = "disabled";
};

&lahaina_snd {
	qcom,msm-mi2s-master = <0>, <1>, <1>, <0>, <1>, <1>;
	qcom,wcd-disabled = <1>;
	qcom,audio-routing =
		"TX DMIC0", "Digital Mic0",
		"TX DMIC1", "Digital Mic1",
		"TX DMIC2", "Digital Mic2",
		"TX DMIC3", "Digital Mic3",
		"TX DMIC4", "Digital Mic4",
		"TX DMIC5", "Digital Mic5",
		"WSA SRC0_INP", "SRC0",
		"WSA_TX DEC0_INP", "TX DEC0 MUX",
		"WSA_TX DEC1_INP", "TX DEC1 MUX",
		"RX_TX DEC0_INP", "TX DEC0 MUX",
		"RX_TX DEC1_INP", "TX DEC1 MUX",
		"RX_TX DEC2_INP", "TX DEC2 MUX",
		"RX_TX DEC3_INP", "TX DEC3 MUX",
		"VA SWR_INPUT", "VA_SWR_CLK",
		"VA_AIF1 CAP", "VA_SWR_CLK",
		"VA_AIF2 CAP", "VA_SWR_CLK",
		"VA_AIF3 CAP", "VA_SWR_CLK",
		"VA DMIC0", "Digital Mic0",
		"VA DMIC1", "Digital Mic1",
		"VA DMIC2", "Digital Mic2",
		"VA DMIC3", "Digital Mic3",
		"VA DMIC4", "Digital Mic4",
		"VA DMIC5", "Digital Mic5",
		"Digital Mic0", "VA MIC BIAS1",
		"Digital Mic1", "VA MIC BIAS1",
		"Digital Mic2", "VA MIC BIAS1",
		"Digital Mic3", "VA MIC BIAS1",
		"Digital Mic4", "VA MIC BIAS1",
		"Digital Mic5", "VA MIC BIAS1";
	qcom,msm-mbhc-hphl-swh;
	qcom,msm-mbhc-gnd-swh;
	qcom,cdc-dmic45-gpios;
	qcom,pri-mi2s-gpios = <&pri_mi2s_gpios>;
	qcom,quat-mi2s-gpios = <&quat_mi2s_gpios>;
	qcom,sen-mi2s-gpios = <&sen_mi2s_gpios>;
	asoc-codec  = <&stub_codec>, <&bolero>,
		      <&ext_disp_audio_codec>;
	asoc-codec-names = "msm-stub-codec.1", "bolero_codec",
			   "msm-ext-disp-audio-codec-rx";
	qcom,wsa-max-devs;
};

&wsa_swr_gpios {
	status = "disabled";
};

&rx_swr_gpios {
	status = "disabled";
};

&tx_swr_gpios {
	status = "disabled";
};

&cdc_dmic45_gpios {
	status = "disabled";
};

&q6core {
	pri_mi2s_gpios: pri_mi2s_pinctrl {
		compatible = "qcom,msm-cdc-pinctrl";
		pinctrl-names = "aud_active", "aud_sleep";
		pinctrl-0 = <&pri_mi2s_sck_active &pri_mi2s_sd0_active &pri_mi2s_ws_active>;
		pinctrl-1 = <&pri_mi2s_sck_sleep &pri_mi2s_sd0_sleep &pri_mi2s_ws_sleep>;
		#gpio-cells = <0>;
	};

	quat_mi2s_gpios: quat_mi2s_pinctrl {
		compatible = "qcom,msm-cdc-pinctrl";
		pinctrl-names = "aud_active", "aud_sleep";
		pinctrl-0 = <&quat_mi2s_sck_active &quat_mi2s_ws_active &quat_mi2s_sd0_active>;
		pinctrl-1 = <&quat_mi2s_sck_sleep &quat_mi2s_ws_sleep &quat_mi2s_sd0_sleep>;
		qcom,lpi-gpios;
		#gpio-cells = <0>;
	};

	sen_mi2s_gpios: sen_mi2s_pinctrl {
		compatible = "qcom,msm-cdc-pinctrl";
		pinctrl-names = "aud_active", "aud_sleep";
		pinctrl-0 = <&lpi_i2s2_sck_active &lpi_i2s2_ws_active
				&lpi_i2s2_sd0_active &lpi_i2s2_sd1_active>;
		pinctrl-1 = <&lpi_i2s2_sck_sleep &lpi_i2s2_ws_sleep
				&lpi_i2s2_sd0_sleep &lpi_i2s2_sd1_sleep>;
		qcom,lpi-gpios;
		#gpio-cells = <0>;
	};
};

&wsa_spkr_en1 {
	status = "disabled";
};

&wsa_spkr_en2 {
	status = "disabled";
};

&wcd938x_rst_gpio {
	status = "disabled";
};

&dai_mi2s0 {
	qcom,msm-mi2s-rx-lines = <1>;
	qcom,msm-mi2s-tx-lines = <0>;
};

&dai_mi2s2 {
	pinctrl-names;
	pinctrl-0;
	pinctrl-1;
};

&dai_mi2s3 {
	qcom,msm-mi2s-rx-lines = <0>;
	qcom,msm-mi2s-tx-lines = <1>;
};

&dai_mi2s5 {
	qcom,msm-mi2s-rx-lines = <2>;
	qcom,msm-mi2s-tx-lines = <1>;
};

&qupv3_se17_i2c {
	status = "ok";

	cs35l45@30 {
		compatible = "cirrus,cs35l45";
		reg = <0x30>;
		VA-supply = <&S10B>;
		VP-supply = <&S10B>;
		reset-gpios = <&tlmm 104 0>;
		interrupt-parent = <&tlmm>;
		interrupts = <90 8>;
		pinctrl-names = "default";
		pinctrl-0 = <&rcv_irq_default>;

		sound-name-prefix = "RCV";
		cirrus,dsp-part-name = "cs35l45-rcv";
		cirrus,fast-switch = "cs35l45-rcv-music.txt", "cs35l45-rcv-outdoor.txt";

		cirrus,asp-sdout-hiz-ctrl = <0x3>;
		cirrus,bst-bpe-il-lim-config {
			bst-bpe-il-lim-thld-hyst = <0x0>;
			bst-bpe-il-lim-thld-del2 = <0x0>;
			bst-bpe-il-lim-thld-del1 = <0x0>;
			bst-bpe-il-lim1-thld = <0x31>;
		};
		cirrus,gpio-ctrl1 {
			gpio-ctrl = <0x02>;
		};
		cirrus,gpio-ctrl2 {
			gpio-ctrl = <0x04>;
		};
	};

	cs35l45@31 {
		compatible = "cirrus,cs35l45";
		reg = <0x31>;
		VA-supply = <&S10B>;
		VP-supply = <&S10B>;
		reset-gpios = <&tlmm 105 0>;
		interrupt-parent = <&tlmm>;
		interrupts = <2 8>;
		pinctrl-names = "default";
		pinctrl-0 = <&spk_irq_default>;

		sound-name-prefix = "SPK";
		cirrus,dsp-part-name = "cs35l45-spk";
		cirrus,fast-switch = "cs35l45-spk-music.txt", "cs35l45-spk-outdoor.txt";

		cirrus,asp-sdout-hiz-ctrl = <0x3>;
		cirrus,bst-bpe-il-lim-config {
			bst-bpe-il-lim-thld-hyst = <0x0>;
			bst-bpe-il-lim-thld-del2 = <0x0>;
			bst-bpe-il-lim-thld-del1 = <0x0>;
			bst-bpe-il-lim1-thld = <0x31>;
		};
		cirrus,gpio-ctrl1 {
			gpio-ctrl = <0x02>;
		};
		cirrus,gpio-ctrl2 {
			gpio-ctrl = <0x04>;
		};
	};

	es928x@49 {
		compatible = "ess,es928x_codec";
		reg = <0x49>;
		//ess,es928x-rst = <&tlmm 148 0>;
		ess,es928x-rx-i2s-master;  // Only required if ES928x is the I2S Master!
		ess,es928x-tx-i2s-master;
		ess,es928x-xosc-freq = <49152000>;
		//ess,es928x-aclk1-freq = <49152000>;
		//ess,es928x-aclk2-freq = <45158400>;
		interrupt-controller;
		#interrupt-cells = <1>;
		ess,es928x-irq = <&tlmm 14 0x00>;
		ess,es928x-rst = <&tlmm 88 0x00>;
		ess,es928x-1p8-en = <&pm8350b_gpios 5 0x0>;
		ess,es928x-3p3-en = <&tlmm 124 0x00>;
		ess,es928x-audio_debug = <&tlmm 123 0x00>;
		interrupt-parent = <&tlmm>;
		interrupts = <14 0x00>;
		interrupt-names = "es928x_irq";
		//pinctrl-names = "ess_active", "ess_suspend";
		//pinctrl-0 = <&ess_intr_default>;
		status = "okay";
	};
};

&qupv3_se11_i2c {
	status = "ok";

	cs35l45_dummy: cs35l45@30 {
		compatible = "cirrus,cs35l45";
		reg = <0x30>;
		asus,dummy;
	};
};

&tlmm {
	rcv_irq_default: rcv_irq_default {
		mux {
			pins = "gpio90";
			function = "gpio";
		};

		config {
			pins = "gpio90";
			drive-strength = <2>;
			bias-pull-up;
			input-enable;
		};
	};

	spk_irq_default: spk_irq_default {
		mux {
			pins = "gpio2";
			function = "gpio";
		};

		config {
			pins = "gpio2";
			drive-strength = <2>;
			bias-pull-up;
			input-enable;
		};
	};
};

/*    ====================================
 *    overlay for lahaina-audio.dtsi - end
 *    ====================================
 */

/*    ====================================
 *    overlay for lahaina-audio-overlay.dtsi - start
 *    ====================================
 */

/*    ====================================
 *    overlay for lahaina-audio-overlay.dtsi - end
 *    ====================================
 */


/*    ====================================
 *    overlay for lahaina-thermal-overlay.dtsi - start
 *    ====================================
 */

/*    ====================================
 *    overlay for lahaina-thermal-overlay.dtsi - end
 *    ====================================
 */

 
/*    ====================================
 *    overlay for lahaina-gpu.dtsi - start
 *    ====================================
 */

/*    ====================================
 *    overlay for lahaina-gpu.dtsi - end
 *    ====================================
 */


/*    ====================================
 *    overlay for lahaina-usb.dtsi - start
 *    ====================================
 */

/*    ====================================
 *    overlay for lahaina-usb.dtsi - end
 *    ====================================
 */
//ASUS_BSP Hank_Jhu : hall sensor for station +++
&soc {
	asustek_lid {
		status = "ok";
		compatible = "asustek_lid";
		pinctrl-names = "asustek_lid_active", "asustek_lid_suspend";
		pinctrl-0 = <&asustek_lid_active>;
		pinctrl-1 = <&asustek_lid_suspend>;
		gpios = <&tlmm 80 0x1>;
		asustek_lid,wakeup;
	};
};
//ASUS_BSP Hank_Jhu : hall sensor for station ---

//ASUS_BSP Hank_Jhu : hall sensor for bumper +++
&soc {
	/* hall sensor for Bumper */
	asustek_lid2 {
		status = "ok";
		compatible = "asustek_lid2";
		pinctrl-names = "asustek_lid2_active", "asustek_lid2_suspend";
		pinctrl-0 = <&asustek_lid2_active>;
		pinctrl-1 = <&asustek_lid2_suspend>;
		gpios = <&tlmm 119 0x1>;
		asustek_lid2,wakeup;
	};
};
//ASUS_BSP Hank_Jhu : hall sensor for bumper ---

&tlmm {
		//ASUS_BSP Hank_Jhu : Hall Sensor +++
		asustek_lid_gpio {
			asustek_lid_active: asustek_lid_active {
				mux {
					pins = "gpio80";
					function = "gpio";
				};

				config {
					pins = "gpio80";
					drive-strength = <2>;
					bias-pull-up;
				};
			};

			asustek_lid_suspend: asustek_lid_suspend {
				mux {
					pins = "gpio80";
					function = "gpio";
				};

				config {
					pins = "gpio80";
					drive-strength = <2>;
					bias-pull-up;
				};
			};
		};
		
		asustek_lid2_gpio {
			asustek_lid2_active: asustek_lid2_active {
				mux {
					pins = "gpio119";
					function = "gpio";
				};

				config {
					pins = "gpio119";
					drive-strength = <2>;
					bias-pull-up;
				};
			};

			asustek_lid2_suspend: asustek_lid2_suspend {
				mux {
					pins = "gpio119";
					function = "gpio";
				};

				config {
					pins = "gpio119";
					drive-strength = <2>;
					bias-pull-up;
				};
			};
		};
		//ASUS_BSP Hank_Jhu : Hall Sensor ---
};


//ASUS_BSP Wifi+++
&soc {
	wlan: qcom,cnss-qca6490@b0000000 {
		compatible = "qcom,cnss-qca6490";
		pinctrl-names = "wlan_en_active", "wlan_en_sleep", "wifi_ant_gpio";
		pinctrl-0 = <&cnss_wlan_en_active>;
		pinctrl-1 = <&cnss_wlan_en_sleep>;
		pinctrl-2 = <&wifi_ant_switch>;
		wlan-asus_ant_141 = <&tlmm 141 0>;
		wlan-asus_ant_142 = <&tlmm 142 0>;
		wlan-asus_ant_144 = <&tlmm 144 0>;
	};
};

&tlmm {
	cnss_pins {
		wifi_ant_switch: wifi_ant_switch {
			mux {
				pins = "gpio141", "gpio142", "gpio144";
				function = "gpio";
			};

			config {
				pins = "gpio141", "gpio142", "gpio144";
				bias-pull-up;
				output-high;
			};
		};
	};
};

